# A31G324 register map
Vendor: ABOV Semiconductor Co., Ltd.; Series: A31G324; File version: 1.0
CPU: CM0PLUS r0p1, little endian, no MPU, no FPU, VTOR, 2 interrupt priority bits
Registers are 32-bit, read-write, reset 0x0 unless marked. A register's access mark holds for its fields unless they carry their own. Offsets are from the block's base; [hi:lo] are bit positions; {n}, {i} and the like mark numbered series; 'fields as' and 'values as' point back to an identical list; <NAME> marks a mode.

## USB (part 2 of 2)
Base 0x50000000
0x834 DIEPEMPMSK — Device IN Endpoint FIFO Empty Interrupt Mask Register
  [15:0] InEpTxfEmpMsk — IN EP Tx FIFO Empty Interrupt Mask Bits (InEpTxfEmpMsk) These bits acts as mask bits for DIEPINTn.TxFEmp interrupt, one bit per IN Endpoint: Bit 0 for IN EP 0, bit 4 for IN EP 4
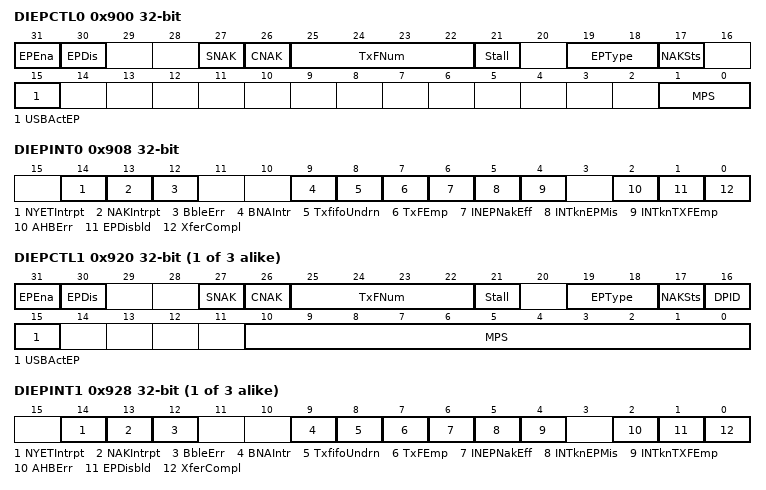
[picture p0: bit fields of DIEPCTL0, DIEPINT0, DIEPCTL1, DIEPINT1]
0x900 DIEPCTL0 — Device Control IN Endpoint 0 Control Register
  [31] EPEna — When Scatter/Gather DMA mode is enabled, for IN endpoints this bit indicates that the descriptor structure and data buffer with data ready to transmit is setup.
  [30] EPDis — Endpoint Disable (EPDis) The application sets this bit to stop transmitting data on an endpoint, even before the transfer for that endpoint is complete. The application must wait for the Endpoint Disabled interrupt before treating the endpoint as disabled. The core clears this bit before setting the Endpoint Disabled Interrupt. The application must Set this bit only if Endpoint Enable is already set for this endpoint.
  [27] SNAK — Set NAK (SNAK) A write to this bit sets the NAK bit for the endpoint. Using this bit, the application can control the transmission of NAK handshakes on an endpoint. The core can also set this bit for an endpoint after a SETUP packet is received on that endpoint.
  [26] CNAK — Clear NAK (CNAK) A write to this bit clears the NAK bit for the endpoint.
  [25:22] TxFNum — TxFIFO Number (TxFNum)
  [21] Stall — TxFIFO Number (TxFNum)
  [19:18] EPType — Endpoint Type (EPType)
  [17] NAKSts — NAK Status (NAKSts)
  [15] USBActEP — USB Active Endpoint (USBActEP) This bit is always SET to 1, indicating that control endpoint 0 is always active in all configurations and interfaces.
  [1:0] MPS — Maximum Packet Size (MPS) Applies to IN and OUT endpoints. The application must program this field with the maximum packet size for the current logical endpoint.
0x908 DIEPINT0 — Device IN Endpoint 0 Interrupt Register
  [14] NYETIntrpt — NYET Interrupt (NYETIntrpt) The core generates this interrupt when a NYET response is transmitted for a non isochronous OUT endpoint.
  [13] NAKIntrpt — NAK Interrupt (NAKInterrupt) The core generates this interrupt when a NAK is transmitted or received by the device. <brIn case of isochronous IN endpoints the interrupt gets generated when a zero length packet is transmitted due to un-availability of data in the TXFifo.
  [12] BbleErr — NAK Interrupt (BbleErr) The core generates this interrupt when babble is received for the endpoint.
  [9] BNAIntr — BNA (Buffer Not Available) Interrupt (BNAIntr) The core generates this interrupt when the descriptor accessed is not ready for the Core to process, such as DMA done.
  [8] TxfifoUndrn — Fifo Underrun (TxfifoUndrn) Applies to IN endpoints only. The core generates this interrupt when it detects a transmit FIFO underrun condition in threshold mode for this endpoint.
  [7] TxFEmp — Transmit FIFO Empty (TxFEmp) This bit is valid only for IN Endpoints This interrupt is asserted when the TxFIFO for this endpoint is either half or completely empty. The half or completely empty status is determined by the TxFIFO Empty Level bit in the Core AHB Configuration register (GAHBCFG.NPTxFEmpLvl)).
  [6] INEPNakEff — IN Endpoint NAK Effective (INEPNakEff) Applies to periodic IN endpoints only. This bit can be cleared when the application clears the IN endpoint NAK by writing to DIEPCTLn.CNAK. This interrupt indicates that the core has sampled the NAK bit Set (either by the application or by the core). The interrupt indicates that the IN endpoint NAK bit Set by the application has taken effect in the core. This interrupt does not guarantee that a NAK handshake is sent on the USB. A STALL bit takes priority over a NAK bit.
  [5] INTknEPMis — IN Token Received with EP Mismatch (INTknEPMis) Applies to non-periodic IN endpoints only. Indicates that the data in the top of the non-periodic TxFIFO belongs to an endpoint other than the one for which the IN token was received. This interrupt is asserted on the endpoint for which the IN token was received.
  [4] INTknTXFEmp — IN Token Received When TxFIFO is Empty (INTknTXFEmp) Applies to non-periodic IN endpoints only. Indicates that an IN token was received when the associated TxFIFO (periodic/non-periodic) was empty. This interrupt is asserted on the endpoint for which the IN token was received.
  [2] AHBErr — AHB Error (AHBErr) Applies to IN and OUT endpoints. This is generated only in Internal DMA mode when there is an AHB error during an AHB read/write. The application can read the corresponding endpoint DMA address register to get the error address.
  [1] EPDisbld — Endpoint Disabled Interrupt (EPDisbld) Applies to IN and OUT endpoints. This bit indicates that the endpoint is disabled per the application's request.
  [0] XferCompl — Transfer Completed Interrupt (XferCompl) Applies to IN and OUT endpoints.
0x914 DIEPDMA0 — Device IN Endpoint 0 DMA Address Register
  [31:0] DMAAddr — DMAAddr This field indicates the base pointer for the descriptor list.
0x918 DTXFSTS0 — Device IN Endpoint Transmit FIFO Status Register 0
  [15:0] INEPTxFSpcAvail ro — IN Endpoint TxFIFO Space Avail (INEPTxFSpcAvail) Indicates the amount of free space available in the Endpoint TxFIFO. Values are in terms of 32-bit words.
0x91C DIEPDMAB0 — Device IN Endpoint 16 Buffer Address Register
  [31:0] DMABufferAddr — Holds the current buffer address.This register is updated as and when the data transfer for the corresponding end point is in progress.
{0x900+0x20*i} DIEPCTL{i} (i=1..3) — Device Control IN Endpoint 1 Control Register
  [31] EPEna — Endpoint Enable (EPEna) Applies to IN and OUT endpoints.
  [30] EPDis — Endpoint Disable (EPDis) Applies to IN and OUT endpoints. The application sets this bit to stop transmitting/receiving data on an endpoint, even before the transfer for that endpoint is complete. The application must wait for the Endpoint Disabled interrupt before treating the endpoint as disabled. The core clears this bit before setting the Endpoint Disabled interrupt. The application must set this bit only if Endpoint Enable is already set for this endpoint.
  [27] SNAK wo — Set NAK (SNAK) A write to this bit sets the NAK bit for the endpoint. Using this bit, the application can control the transmission of NAK handshakes on an endpoint. The core can also Set this bit for an endpoint after a SETUP packet is received on that endpoint.
  [26] CNAK wo — Clear NAK (CNAK) A write to this bit clears the NAK bit for the endpoint.
  [25:22] TxFNum — TxFIFO Number (TxFNum) Dedicated FIFO Operation: These bits specify the FIFO number associated with this endpoint. Each active IN endpoint must be programmed to a separate FIFO number. This field is valid only for IN endpoints.
  [21] Stall — STALL Handshake (Stall) Applies to non-control, non-isochronous IN and OUT endpoints only. The application sets this bit to stall all tokens from the USB host to this endpoint. If a NAK bit, Global Non-periodic IN NAK, or Global OUT NAK is set along with this bit, the STALL bit takes priority. Only the application can clear this bit, never the core. Applies to control endpoints only. The application can only set this bit, and the core clears it, when a SETUP token is received for this endpoint. If a NAK bit, Global Non-periodic IN NAK, or Global OUT NAK is set along with this bit, the STALL bit takes priority. Irrespective of this bit's setting, the core always responds to SETUP data packets with an ACK handshake.
  [19:18] EPType ro — Endpoint Type (EPType) This is the transfer type supported by this logical endpoint.
  [17] NAKSts ro — NAK Status (NAKSts)
  [16] DPID ro — Endpoint Data PID (DPID) Applies to interrupt/bulk IN and OUT endpoints only. Contains the PID of the packet to be received or transmitted on this endpoint. The application must program the PID of the first packet to be received or transmitted on this endpoint, after the endpoint is activated. The applications use the SetD1PID and SetD0PID fields of this register to program either DATA0 or DATA1 PID.
  [15] USBActEP ro — USB Active Endpoint (USBActEP) Indicates whether this endpoint is active in the current configuration and interface. The core clears this bit for all endpoints (other than EP 0) after detecting a USB reset. After receiving the SetConfiguration and SetInterface commands, the application must program endpoint registers accordingly and set this bit.
  [10:0] MPS — Maximum Packet Size (MPS) The application must program this field with the maximum packet size for the current logical endpoint. This value is in bytes.
{0x908+0x20*i} DIEPINT{i} (i=1..3) — Device IN Endpoint 1 Interrupt Register
  [14] NYETIntrpt — NYET Interrupt (NYETIntrpt) The core generates this interrupt when a NYET response is transmitted for a non isochronous OUT endpoint.
  [13] NAKIntrpt — NAK Interrupt (NAKInterrupt) The core generates this interrupt when a NAK is transmitted or received by the device. In case of isochronous IN endpoints the interrupt gets generated when a zero length packet is transmitted due to un-availability of data in the TXFifo.
  [12] BbleErr — NAK Interrupt (BbleErr) The core generates this interrupt when babble is received for the endpoint.
  [9] BNAIntr — BNA (Buffer Not Available) Interrupt (BNAIntr) The core generates this interrupt when the descriptor accessed is not ready for the Core to process, such as Host busy or DMA done.
  [8] TxfifoUndrn — Fifo Underrun (TxfifoUndrn) Applies to IN endpoints Only This bit is valid only If thresholding is enabled. The core generates this interrupt when it detects a transmit FIFO underrun condition for this endpoint.
  [7] TxFEmp ro — Transmit FIFO Empty (TxFEmp) This bit is valid only for IN endpoints This interrupt is asserted when the TxFIFO for this endpoint is either half or completely empty. The half or completely empty status is determined by the TxFIFO Empty Level bit in the Core AHB Configuration register (GAHBCFG.NPTxFEmpLvl)).
  [6] INEPNakEff — IN Endpoint NAK Effective (INEPNakEff) Applies to periodic IN endpoints only. This bit can be cleared when the application clears the IN endpoint NAK by writing to DIEPCTLn.CNAK. This interrupt indicates that the core has sampled the NAK bit Set (either by the application or by the core). The interrupt indicates that the IN endpoint NAK bit Set by the application has taken effect in the core. This interrupt does not guarantee that a NAK handshake is sent on the USB. A STALL bit takes priority over a NAK bit.
  [5] INTknEPMis — IN Token Received with EP Mismatch (INTknEPMis) Applies to non-periodic IN endpoints only. Indicates that the data in the top of the non-periodic TxFIFO belongs to an endpoint other than the one for which the IN token was received. This interrupt is asserted on the endpoint for which the IN token was received.
  [4] INTknTXFEmp — IN Token Received When TxFIFO is Empty (INTknTXFEmp) Applies to non-periodic IN endpoints only. Indicates that an IN token was received when the associated TxFIFO (periodic/non-periodic) was empty. This interrupt is asserted on the endpoint for which the IN token was received.
  [2] AHBErr — AHB Error (AHBErr) Applies to IN and OUT endpoints. This is generated only in Internal DMA mode when there is an AHB error during an AHB read/write. The application can read the corresponding endpoint DMA address register to get the error address.
  [1] EPDisbld — Endpoint Disabled Interrupt (EPDisbld) Applies to IN and OUT endpoints. This bit indicates that the endpoint is disabled per the application's request.
  [0] XferCompl — Transfer Completed Interrupt (XferCompl) Applies to IN and OUT endpoints. + When Scatter/Gather DMA mode is enabled -For IN endpoint this field indicates that the requested data from the descriptor is moved from external system memory to internal FIFO. -For OUT endpoint this field indicates that the requested data from the internal FIFO is moved to external system memory. This interrupt is generated only when the corresponding endpoint descriptor is closed, and the IOC bit for the corresponding descriptor is set.
{0x914+0x20*i} DIEPDMA{i} (i=1..3) — Device IN Endpoint 1 DMA Address Register
  [31:0] DMAAddr — Holds the start address of the external memory for storing or fetching endpoint data. Note: For control endpoints, this field stores control OUT data packets as well as SETUP transaction data packets. When more than three SETUP packets are received back-to-back, the SETUP data packet in the memory is overwritten. This register is incremented on every AHB transaction. The application can give only a DWORD-aligned address.
{0x918+0x20*i} DTXFSTS{i} (i=1..3) — Device IN Endpoint Transmit FIFO Status Register 1
  fields as DTXFSTS0
{0x91C+0x20*i} DIEPDMAB{i} (i=1..4) — Device IN Endpoint 16 Buffer Address Register
  [31:0] DMABufferAddr — Holds the current buffer address. This register is updated as and when the data transfer for the corresponding end point is in progress. This register is present only in Scatter/Gather DMA mode. Otherwise this field is reserved.
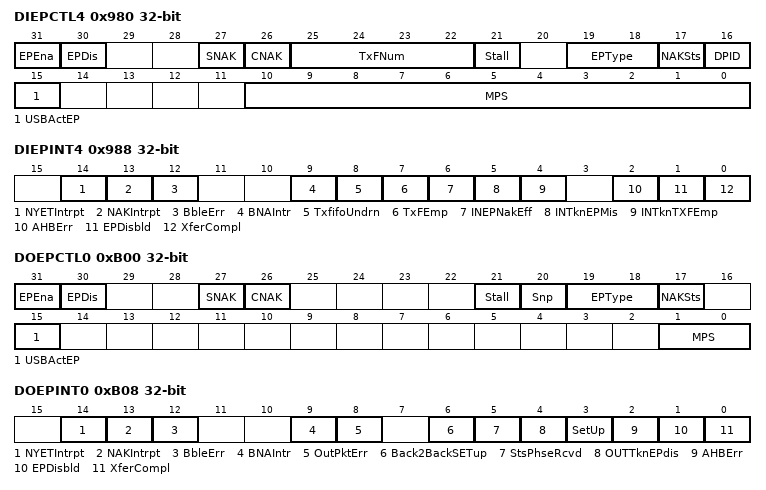
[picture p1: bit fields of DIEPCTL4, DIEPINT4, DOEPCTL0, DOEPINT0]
0x980 DIEPCTL4 — Device Control IN Endpoint 4 Control Register
  fields as DIEPCTL1
0x988 DIEPINT4 — Device IN Endpoint 4 Interrupt Register
  fields as DIEPINT1
0x994 DIEPDMA4 — Device IN Endpoint 4 DMA Address Register
  fields as DIEPDMA1
0x998 DTXFSTS4 — Device IN Endpoint Transmit FIFO Status Register 4
  fields as DTXFSTS0
0xB00 DOEPCTL0 — Device Control OUT Endpoint 0 Control Register
  [31] EPEna — Endpoint Enable (EPEna) + When Scatter/Gather DMA mode is enabled, for OUT endpoints this bit indicates that the descriptor structure and data buffer to receive data is setup. + The core clears this bit before setting any of the following interrupts on this endpoint: -SETUP Phase Done -Endpoint Disabled -Transfer Completed Note: This bit must be set for the core to transfer SETUP data packets into memory.
  [30] EPDis — Endpoint Disable (EPDis) The application cannot disable control OUT endpoint 0.
  [27] SNAK wo — Set NAK (SNAK) A write to this bit sets the NAK bit for the endpoint. Using this bit, the application can control the transmission of NAK handshakes on an endpoint. The core can also set bit on a Transfer Completed interrupt, or after a SETUP is received on the endpoint.
  [26] CNAK wo — Clear NAK (CNAK) A write to this bit clears the NAK bit for the endpoint.
  [21] Stall — STALL Handshake (Stall) The application can only set this bit, and the core clears it, when a SETUP token is received for this endpoint. If a NAK bit or Global OUT NAK is Set along with this bit, the STALL bit takes priority. Irrespective of this bit's setting, the core always responds to SETUP data packets with an ACK handshake.
  [20] Snp — Snoop Mode (Snp) This bit configures the endpoint to Snoop mode. In Snoop mode, the core does not check the correctness of OUT packets before transferring them to application memory.
  [19:18] EPType ro — Endpoint Type (EPType) Hardcoded to 2'b00 for control.
  [17] NAKSts ro — NAK Status (NAKSts) Indicates the following: +1'b0: The core is transmitting non-NAK handshakes based on the FIFO status. +1'b1: The core is transmitting NAK handshakes on this endpoint. When either the application or the core sets this bit, the core stops receiving data, even If there is space in the RxFIFO to accommodate the incoming packet. Irrespective of this bit's setting, the core always responds to SETUP data packets with an ACK handshake.
  [15] USBActEP ro — USB Active Endpoint (USBActEP) This bit is always set to 1, indicating that a control endpoint 0 is always active in all configurations and interfaces.
  [1:0] MPS — Maximum Packet Size (MPS) The maximum packet size for control OUT endpoint 0 is the same as what is programmed in control IN Endpoint 0.
0xB08 DOEPINT0 — Device OUT Endpoint 0 Interrupt Register
  [14] NYETIntrpt — NYET Interrupt (NYETIntrpt) The core generates this interrupt when a NYET response is transmitted for a non isochronous OUT endpoint.
  [13] NAKIntrpt — NAK Interrupt (NAKInterrupt) The core generates this interrupt when a NAK is transmitted or received by the device. In case of isochronous IN endpoints the interrupt gets generated when a zero length packet is transmitted due to un-availability of data in the TXFifo.
  [12] BbleErr — NAK Interrupt (BbleErr) The core generates this interrupt when babble is received for the endpoint.
  [9] BNAIntr — BNA (Buffer Not Available) Interrupt (BNAIntr) The core generates this interrupt when the descriptor accessed is not ready for the core to process, such as Host busy or DMA done.
  [8] OutPktErr — OUT Packet Error (OutPktErr) Applies to OUT endpoints Only This interrupt is valid only when thresholding is enabled. This interrupt is asserted when the core detects an overflow or a CRC error for non-Isochronous OUT packet.
  [6] Back2BackSETup — Back-to-Back SETUP Packets Received (Back2BackSETup) Applies to Control OUT endpoints only. This bit indicates that the core has received more than three back-to-back SETUP packets for this particular endpoint. For information about handling this interrupt,
  [5] StsPhseRcvd — Status Phase Received for Control Write (StsPhseRcvd) This interrupt is valid only for Control OUT endpoints. This interrupt is generated only after the core has transferred all the data that the host has sent during the data phase of a control write transfer, to the system memory buffer. The interrupt indicates to the application that the host has switched from data phase to the status phase of a Control Write transfer. The application can use this interrupt to ACK or STALL the Status phase, after it has decoded the data phase.
  [4] OUTTknEPdis — OUT Token Received When Endpoint Disabled (OUTTknEPdis) Applies only to control OUT endpoints. Indicates that an OUT token was received when the endpoint was not yet enabled. This interrupt is asserted on the endpoint for which the OUT token was received.
  [3] SetUp — SETUP Phase Done (SetUp) Applies to control OUT endpoints only. Indicates that the SETUP phase for the control endpoint is complete and no more back-to-back SETUP packets were received for the current control transfer. On this interrupt, the application can decode the received SETUP data packet.
  [2] AHBErr — AHB Error (AHBErr) Applies to IN and OUT endpoints. This is generated when there is an AHB error during an AHB read/write. The application can read the corresponding endpoint DMA address register to get the error address.
  [1] EPDisbld — Endpoint Disabled Interrupt (EPDisbld) Applies to IN and OUT endpoints. This bit indicates that the endpoint is disabled per the application's request.
  [0] XferCompl — Transfer Completed Interrupt (XferCompl) Applies to IN and OUT endpoints. + For IN endpoint this field indicates that the requested data from the descriptor is moved from external system memory to internal FIFO. + For OUT endpoint this field indicates that the requested data from the internal FIFO is moved to external system memory. This interrupt is generated only when the corresponding endpoint descriptor is closed, and the IOC bit for the corresponding descriptor is Set.
0xB14 DOEPDMA0 — Device OUT Endpoint 0 DMA Address Register
  [31:0] DMAAddr — Holds the start address of the external memory for storing or fetching endpoint data. Note: For control endpoints, this field stores control OUT data packets as well as SETUP transaction data packets. When more than three SETUP packets are received back-to-back, the SETUP data packet in the memory is overwritten. This register is incremented on every AHB transaction. The application can give only a DWORD-aligned address. When Scatter/Gather DMA mode is enabled, this field indicates the base pointer for the descriptor list.
0xB1C DOEPDMAB0 — Device OUT Endpoint 16 Buffer Address Register
  [31:0] DMABufferAddr ro — Holds the current buffer address. This register is updated as and when the data transfer for the corresponding end point is in progress. This register is present only in Scatter/Gather DMA mode. Otherwise this field is reserved.
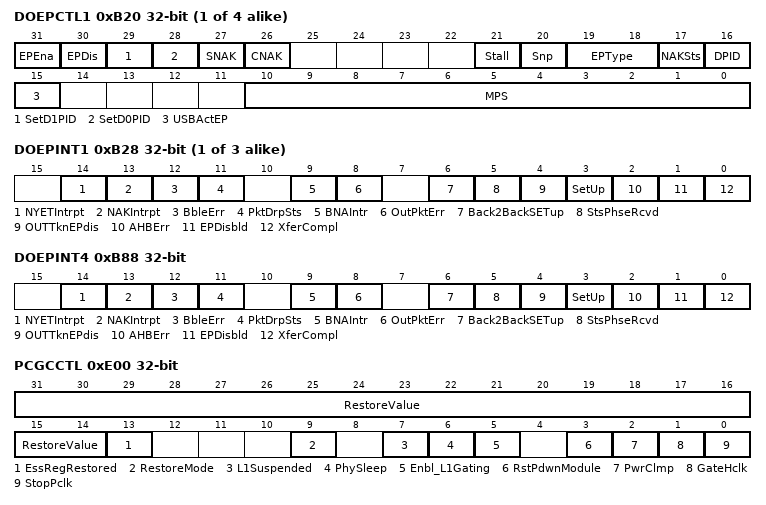
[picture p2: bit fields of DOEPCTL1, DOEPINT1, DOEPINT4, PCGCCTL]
{0xB00+0x20*i} DOEPCTL{i} (i=1..4) — Device Control OUT Endpoint {i} Control Register
  [31] EPEna — Endpoint Enable (EPEna) Applies to IN and OUT endpoints. + For IN endpoints this bit indicates that the descriptor structure and data buffer with data ready to transmit is setup. + For OUT endpoint it indicates that the descriptor structure and data buffer to receive data is setup. The core clears this bit before setting any of the following interrupts on this endpoint: + SETUP Phase Done + Endpoint Disabled + Transfer Completed Note: For control endpoints in DMA mode, this bit must be set to be able to transfer SETUP data packets in memory.
  [30] EPDis — Endpoint Disable (EPDis) Applies to IN and OUT endpoints. The application sets this bit to stop transmitting/receiving data on an endpoint, even before the transfer for that endpoint is complete. The application must wait for the Endpoint Disabled interrupt before treating the endpoint as disabled. The core clears this bit before setting the Endpoint Disabled interrupt. The application must set this bit only if Endpoint Enable is already set for this endpoint.
  [29] SetD1PID wo — Set DATA1 PID (SetD1PID) + Applies to interrupt and bulk IN and OUT endpoints only. + Writing to this field sets the Endpoint Data PID (DPID) field in this register to DATA1. Values: + 0x0 (DISABLED): Disables Set DATA1 PID or Do not force Odd Frame + 0x1 (ENABLED): Set Endpoint Data PID to DATA1 or Sets EO_FrNum field to odd (micro)frame
  [28] SetD0PID wo — Set DATA0 PID (SetD0PID) + Applies to interrupt/bulk IN and OUT endpoints only. + Writing to this field sets the Endpoint Data PID (DPID) field in this register to DATA0. Values: + 0x0 (DISABLED): Disables Set DATA0 PID or Do not force Even Frame + 0x1 (ENABLED): Set Endpoint Data PID to DATA0 or Sets EO_FrNum field to odd (micro)frame
  [27] SNAK wo — Set NAK (SNAK) A write to this bit sets the NAK bit for the endpoint. Using this bit, the application can control the transmission of NAK handshakes on an endpoint. The core can also set this bit for an endpoint after a SETUP packet is received on that endpoint.
  [26] CNAK wo — Clear NAK (CNAK) A write to this bit clears the NAK bit for the endpoint.
  [21] Stall — STALL Handshake (Stall) Applies to non-control, non-isochronous IN and OUT endpoints only. The application sets this bit to stall all tokens from the USB host to this endpoint. If a NAK bit, Global Non-periodic IN NAK, or Global OUT NAK is set along with this bit, the STALL bit takes priority. Only the application can clear this bit, never the core. Applies to control endpoints only. The application can only set this bit, and the core clears it, when a SETUP token is received for this endpoint. If a NAK bit, Global Non-periodic IN NAK, or Global OUT NAK is set along with this bit, the STALL bit takes priority. Irrespective of this bit's setting, the core always responds to SETUP data packets with an ACK handshake.
  [20] Snp — Snoop Mode (Snp) Applies to OUT endpoints only. This bit configures the endpoint to Snoop mode. In Snoop mode, the core does not check the correctness of OUT packets before transferring them to application memory.
  [19:18] EPType ro — Endpoint Type (EPType) This is the transfer type supported by this logical endpoint. + 2'b00: Control + 2'b01: Isochronous + 2'b10: Bulk + 2'b11: Interrupt
  [17] NAKSts ro — NAK Status (NAKSts) Indicates the following: + 1'b0: The core is transmitting non-NAK handshakes based on the FIFO status. + 1'b1: The core is transmitting NAK handshakes on this endpoint. When either the application or the core sets this bit: + The core stops receiving any data on an OUT endpoint, even if there is space in the RxFIFO to accommodate the incoming packet. + For non-isochronous IN endpoints: The core stops transmitting any data on an IN endpoint, even if there data is available in the TxFIFO. + For isochronous IN endpoints: The core sends out a zero-length data packet, even if there data is available in the TxFIFO. Irrespective of this bit's setting, the core always responds to SETUP data packets with an ACK handshake.
  [16] DPID ro — Endpoint Data PID (DPID) Applies to interrupt/bulk IN and OUT endpoints only. Contains the PID of the packet to be received or transmitted on this endpoint. The application must program the PID of the first packet to be received or transmitted on this endpoint, after the endpoint is activated. The applications use the SetD1PID and SetD0PID fields of this register to program either DATA0 or DATA1 PID.
  [15] USBActEP ro — USB Active Endpoint (USBActEP) Indicates whether this endpoint is active in the current configuration and interface. The core clears this bit for all endpoints (other than EP 0) after detecting a USB reset. After receiving the SetConfiguration and SetInterface commands, the application must program endpoint registers accordingly and set this bit.
  [10:0] MPS — Maximum Packet Size (MPS) The application must program this field with the maximum packet size for the current logical endpoint. This value is in bytes.
{0xB08+0x20*i} DOEPINT{i} (i=1..3) — Device OUT Endpoint {i} Interrupt Register
  [14] NYETIntrpt — NYET Interrupt (NYETIntrpt) The core generates this interrupt when a NYET response is transmitted for a non isochronous OUT endpoint.
  [13] NAKIntrpt — NAK Interrupt (NAKInterrupt) The core generates this interrupt when a NAK is transmitted or received by the device. In case of isochronous IN endpoints the interrupt gets generated when a zero length packet is transmitted due to un-availability of data in the TXFifo.
  [12] BbleErr — NAK Interrupt (BbleErr) The core generates this interrupt when babble is received for the endpoint.
  [11] PktDrpSts — Packet Drop Status (PktDrpSts) This bit indicates to the application that an ISOC OUT packet has been dropped. This bit does not have an associated mask bit and does not generate an interrupt. Dependency: This bit is valid in non Scatter/Gather DMA mode when periodic transfer interrupt feature is selected.
  [9] BNAIntr — BNA (Buffer Not Available) Interrupt (BNAIntr) This bit is valid only when Scatter/Gather DMA mode is enabled. The core generates this interrupt when the descriptor accessed is not ready for the Core to process, such as Host busy or DMA done
  [8] OutPktErr — OUT Packet Error (OutPktErr) Applies to OUT endpoints Only This interrupt is valid only when thresholding is enabled. This interrupt is asserted when the core detects an overflow or a CRC error for non-Isochronous OUT packet.
  [6] Back2BackSETup — Back-to-Back SETUP Packets Received (Back2BackSETup) Applies to Control OUT endpoints only. This bit indicates that the core has received more than three back-to-back SETUP packets for this particular endpoint. For information about handling this interrupt,
  [5] StsPhseRcvd — Status Phase Received for Control Write (StsPhseRcvd) This interrupt is valid only for Control OUT endpoints. This interrupt is generated only after the core has transferred all the data that the host has sent during the data phase of a control write transfer, to the system memory buffer. The interrupt indicates to the application that the host has switched from data phase to the status phase of a Control Write transfer. The application can use this interrupt to ACK or STALL the Status phase, after it has decoded the data phase. This is applicable only in Case of Scatter Gather DMA mode.
  [4] OUTTknEPdis — OUT Token Received When Endpoint Disabled (OUTTknEPdis) Applies only to control OUT endpoints. Indicates that an OUT token was received when the endpoint was not yet enabled. This interrupt is asserted on the endpoint for which the OUT token was received.
  [3] SetUp — SETUP Phase Done (SetUp) Applies to control OUT endpoints only. Indicates that the SETUP phase for the control endpoint is complete and no more back-to-back SETUP packets were received for the current control transfer. On this interrupt, the application can decode the received SETUP data packet.
  [2] AHBErr — AHB Error (AHBErr) Applies to IN and OUT endpoints. This is generated only in Internal DMA mode when there is an AHB error during an AHB read/write. The application can read the corresponding endpoint DMA address register to get the error address.
  [1] EPDisbld — Endpoint Disabled Interrupt (EPDisbld) Applies to IN and OUT endpoints. This bit indicates that the endpoint is disabled per the application's request.
  [0] XferCompl — Transfer Completed Interrupt (XferCompl) Applies to IN and OUT endpoints. + When Scatter/Gather DMA mode is enabled -For IN endpoint this field indicates that the requested data from the descriptor is moved from external system memory to internal FIFO. -For OUT endpoint this field indicates that the requested data from the internal FIFO is moved to external system memory. This interrupt is generated only when the corresponding endpoint descriptor is closed, and the IOC bit for the corresponding descriptor is Set.
{0xB14+0x20*i} DOEPDMA{i} (i=1..4) — Device OUT Endpoint {i} DMA Address Register
  [31:0] DMAAddr — Holds the start address of the external memory for storing or fetching endpoint data. Note: For control endpoints, this field stores control OUT data packets as well as SETUP transaction data packets. When more than three SETUP packets are received back-to-back, the SETUP data packet in the memory is overwritten. This register is incremented on every AHB transaction. The application can give only a DWORD-aligned address. + When Scatter/Gather DMA mode is enabled, this field indicates the base pointer for the descriptor list.
{0xB1C+0x20*i} DOEPDMAB{i} (i=1..4) — Device OUT Endpoint 16 Buffer Address Register
  [31:0] DMABufferAddr ro — Holds the current buffer address.This register is updated as and when the data transfer for the corresponding end point is in progress.
0xB88 DOEPINT4 — Device OUT Endpoint 4 Interrupt Register
  [14] NYETIntrpt — NYET Interrupt (NYETIntrpt) The core generates this interrupt when a NYET response is transmitted for a non isochronous OUT endpoint.
  [13] NAKIntrpt — NAK Interrupt (NAKInterrupt) The core generates this interrupt when a NAK is transmitted or received by the device. In case of isochronous IN endpoints the interrupt gets generated when a zero length packet is transmitted due to un-availability of data in the TXFifo.
  [12] BbleErr — NAK Interrupt (BbleErr) The core generates this interrupt when babble is received for the endpoint.
  [11] PktDrpSts — Packet Drop Status (PktDrpSts) This bit indicates to the application that an ISOC OUT packet has been dropped. This bit does not have an associated mask bit and does not generate an interrupt. Dependency: This bit is valid in non Scatter/Gather DMA mode when periodic transfer interrupt feature is selected.
  [9] BNAIntr — BNA (Buffer Not Available) Interrupt (BNAIntr) This bit is valid only when Scatter/Gather DMA mode is enabled. The core generates this interrupt when the descriptor accessed is not ready for the Core to process, such as Host busy or DMA done
  [8] OutPktErr — OUT Packet Error (OutPktErr) Applies to OUT endpoints Only This interrupt is valid only when thresholding is enabled. This interrupt is asserted when the core detects an overflow or a CRC error for non-Isochronous OUT packet.
  [6] Back2BackSETup — Back-to-Back SETUP Packets Received (Back2BackSETup) Applies to Control OUT endpoints only. This bit indicates that the core has received more than three back-to-back SETUP packets for this particular endpoint. For information about handling this interrupt,
  [5] StsPhseRcvd — Status Phase Received for Control Write (StsPhseRcvd) This interrupt is valid only for Control OUT endpoints. This interrupt is generated only after the core has transferred all the data that the host has sent during the data phase of a control write transfer, to the system memory buffer. The interrupt indicates to the application that the host has switched from data phase to the status phase of a Control Write transfer. The application can use this interrupt to ACK or STALL the Status phase, after it has decoded the data phase. This is applicable only in Case of Scatter Gather DMA mode.
  [4] OUTTknEPdis — OUT Token Received When Endpoint Disabled (OUTTknEPdis) Applies only to control OUT endpoints. Indicates that an OUT token was received when the endpoint was not yet enabled. This interrupt is asserted on the endpoint for which the OUT token was received.
  [3] SetUp — SETUP Phase Done (SetUp) Applies to control OUT endpoints only. Indicates that the SETUP phase for the control endpoint is complete and no more back-to-back SETUP packets were received for the current control transfer. On this interrupt, the application can decode the received SETUP data packet.
  [2] AHBErr — AHB Error (AHBErr) Applies to IN and OUT endpoints. This is generated only in Internal DMA mode when there is an AHB error during an AHB read/write. The application can read the corresponding endpoint DMA address register to get the error address.
  [1] EPDisbld — Endpoint Disabled Interrupt (EPDisbld) Applies to IN and OUT endpoints. This bit indicates that the endpoint is disabled per the application's request.
  [0] XferCompl — Transfer Completed Interrupt (XferCompl) Applies to IN and OUT endpoints. + When Scatter/Gather DMA mode is enabled - For IN endpoint this field indicates that the requested data from the descriptor is moved from external system memory to internal FIFO. -For OUT endpoint this field indicates that the requested data from the internal FIFO is moved to external system memory. This interrupt is generated only when the corresponding endpoint descriptor is closed, and the IOC bit for the corresponding descriptor is Set.
0xE00 PCGCCTL — Power and Clock Gating Control Register
  [31:14] RestoreValue — Restore Value (RestoreValue) When Hibernation mode is enabled, the RestoreValue needs to be be read at SAVE_POINT to store in non-volatile memory and at RESTORE_POINT restored before PCGCCTL.EssRegRestored field is set.
  [13] EssRegRestored — Essential Register Values Restored (EssRegRestored) A write of one into this field indicates that register values of essential registers have been restored. For definition of essential registers, refer programming flow section for Hibernation.
  [9] RestoreMode — Restore Mode (RestoreMode) The application should program this bit to specify the restore mode during RESTORE POINT before programming PCGCCTL.EssRegRest bit is set.
  [7] L1Suspended — L1 Deep Sleep Indicates that the PHY is in deep sleep when in L1 state.
  [6] PhySleep — PHY In Sleep Indicates that the PHY is in Sleep State.
  [5] Enbl_L1Gating — Enable Sleep Clock Gating If this bit is set, core internal clock gating is enabled sleep state if utmi_l1_suspend_n cannot be asserted by the core. The PHY clock will not be gated in sleep state if Enbl_L1Gating is not set.
  [3] RstPdwnModule — Reset Power-Down Modules (RstPdwnModule) This bit is valid only in Partial Power-Down mode. + The application sets this bit when the power is turned off. + The application clears this bit after the power is turned on and the PHY clock is up. Note: The R/W of all core registers are possible only when this bit is set to 1b0.
  [2] PwrClmp — Power Clamp (PwrClmp) This bit is valid only in Partial Power-Down mode + The application sets this bit before the power is turned off to clamp the signals between the power-on modules and the power-off modules. + The application clears the bit to disable the clamping before the power is turned on.
  [1] GateHclk — Gate Hclk (GateHclk) + The application sets this bit to gate hclk to modules other than the AHB Slave and Master and wakeup logic when the USB is suspended or the session is not valid. + The application clears this bit when the USB is resumed or a new session starts.
  [0] StopPclk — Stop Pclk (StopPclk) + The application sets this bit to stop the PHY clock (phy_clk) when the USB is suspended, the session is not valid, or the device is disconnected. + The application clears this bit when the USB is resumed or a new session starts.
